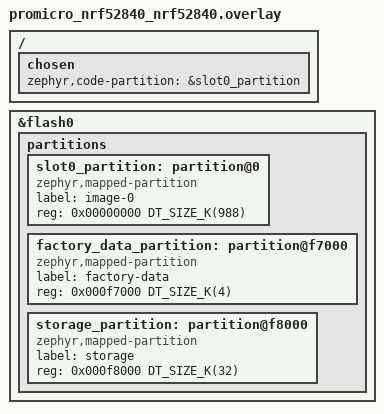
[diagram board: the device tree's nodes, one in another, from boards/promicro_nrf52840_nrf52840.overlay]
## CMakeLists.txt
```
# BLE-to-Matter-over-Thread gateway.
# Based on the nRF Connect SDK Matter Bridge application
# (Copyright (c) 2023 Nordic Semiconductor ASA, LicenseRef-Nordic-5-Clause).
#

cmake_minimum_required(VERSION 3.20.0)

find_package(Zephyr HINTS $ENV{ZEPHYR_BASE})

project(ble-matter-gateway)

# Bridge core, Matter identity, network log: firmware/common
include(${CMAKE_CURRENT_SOURCE_DIR}/../common/common.cmake)

target_include_directories(app PRIVATE
  src
  src/ble
  src/ble/data_providers
  src/sensors
  src/thermostat
)

target_sources(app PRIVATE
  src/app_task.cpp
  src/main.cpp
  src/bridge_shell.cpp
  src/zcl_callbacks.cpp
  src/ble/ble_connectivity_manager.cpp
  src/ble/ble_bridged_device_factory.cpp
  ${GATEWAY_BRIDGED_DEVICE_TYPES}/temperature_sensor.cpp
  ${GATEWAY_BRIDGED_DEVICE_TYPES}/humidity_sensor.cpp
  ${GATEWAY_BRIDGED_DEVICE_TYPES}/thermostat.cpp
  src/thermostat/eq3_client.cpp
  src/ble/data_providers/ble_environmental_data_provider.cpp
  src/sensors/bthome.c
  src/sensors/sensor_scanner.c
  src/sensors/sensor_shell.cpp
  src/sensors/bthome_sensor_provider.cpp
  src/sensors/bthome_sensor_manager.cpp
)

# Status page (firmware/common/web): src/web/index.html and its JSON
target_sources_ifdef(CONFIG_GATEWAY_WEB app PRIVATE src/web_status.cpp)

ncs_configure_data_model()
```

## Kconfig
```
#
# BLE-to-Matter-over-Thread gateway.
# Based on the nRF Connect SDK Matter Bridge application
# (Copyright (c) 2023 Nordic Semiconductor, LicenseRef-Nordic-5-Clause).
#
mainmenu "BLE-to-Matter-over-Thread Gateway"

config BRIDGE_TEMPERATURE_SENSOR_BRIDGED_DEVICE
	bool "Support for Temperature Sensor bridged device"
	default y

config BRIDGE_HUMIDITY_SENSOR_BRIDGED_DEVICE
	bool "Support for Humidity Sensor bridged device"
	default y

# The gateway always bridges real Bluetooth LE devices; the simulated providers of
# the original sample were removed. The symbol is kept because the bridge core
# code uses it to enable the Bluetooth LE parts.
config BRIDGED_DEVICE_BT
	bool
	default y

config BT_CENTRAL
	default y

config BT_SCAN
	default y

config BT_SCAN_FILTER_ENABLE
	default y

# Configure how many Bluetooth LE service UUIDs the bridge can scan for.
config BT_SCAN_UUID_CNT
	default 2

config BT_SCAN_ADDRESS_CNT
	default 1

config BT_GATT_CLIENT
	default y

config BT_GATT_DM
	default y

config BT_EXT_ADV
	default y

config BT_SMP
	default y

if BT_SMP

config BT_SETTINGS
	default y

# Use two Bluetooth LE identities. The first one is used by the peripheral for Matter service
# advertising purposes, and the other is used by the bridge central.
config BT_ID_MAX
	default 2

config BT_EXT_ADV_LEGACY_SUPPORT
	default y

endif

config BRIDGE_BLE_DEVICE_POLLING_INTERVAL
	int "BLE humidity measurement readout polling interval in ms"
	default 3000

if BRIDGE_TEMPERATURE_SENSOR_BRIDGED_DEVICE

# Matter TemperatureMeasurement uses 0.01 degC. (The original sample used -20/60, i.e. -0.20..0.60 degC.)
config BRIDGE_TEMPERATURE_SENSOR_MIN_MEASURED_VALUE
	int "Minimum measured value of bridged temperature sensors (0.01 degC)"
	default -4000

config BRIDGE_TEMPERATURE_SENSOR_MAX_MEASURED_VALUE
	int "Maximum measured value of bridged temperature sensors (0.01 degC)"
	default 12500

endif

if BRIDGE_HUMIDITY_SENSOR_BRIDGED_DEVICE

# Matter RelativeHumidityMeasurement uses 0.01 %. (The original sample used 0/100, i.e. 0..1 %.)
config BRIDGE_HUMIDITY_SENSOR_MIN_MEASURED_VALUE
	int "Minimum measured value of bridged humidity sensors (0.01 %)"
	default 0

config BRIDGE_HUMIDITY_SENSOR_MAX_MEASURED_VALUE
	int "Maximum measured value of bridged humidity sensors (0.01 %)"
	default 10000

endif

menu "Gateway sensor scanner"

config GATEWAY_SENSOR_SCAN_INTERVAL
	int "Background scan interval (x0.625 ms)"
	default 160
	help
	  Time between scan windows of the background passive scan for BTHome sensors.
	  Default: 160 (100 ms).

config GATEWAY_SENSOR_SCAN_WINDOW
	int "Background scan window (x0.625 ms)"
	default 40
	help
	  Listening time per scan interval. Keep it well below the interval so Thread
	  keeps enough radio time. Default: 40 (25 ms, 25 % duty cycle).

config GATEWAY_SENSOR_SCAN_RETRY_MS
	int "Background scan restart check interval (ms)"
	default 2000

config GATEWAY_SENSOR_SEEN_MAX
	int "Number of sensors kept in the 'heard' table"
	default 16

config GATEWAY_SENSOR_SCAN_PAUSE_CONNECT_MS
	int "Background scan pause while a GATT connection is being created (ms)"
	default 5000

config GATEWAY_BTHOME_AUTO_ADD
	bool "Add BTHome sensors to Matter automatically"
	default y
	help
	  Add a sensor as a Temperature Sensor and a Humidity Sensor endpoint on its
	  first BTHome packet with measurements. Removed sensors are ignored from then
	  on (shell: gateway remove / gateway unignore).

config GATEWAY_BTHOME_MAX_SENSORS
	int "Maximum number of bridged BTHome devices (sensors and thermostats)"
	default 10
	help
	  Each device uses one bridge provider; a sensor uses two dynamic
	  endpoints, a thermostat one. See BRIDGE_MAX_BRIDGED_DEVICES_NUMBER and
	  BRIDGE_MAX_DYNAMIC_ENDPOINTS_NUMBER.

config GATEWAY_EQ3_NAME_WAIT_S
	int "Wait this long for a new eQ-3 thermostat's name before adding it (s)"
	default 20
	range 0 120
	help
	  A renamed eQ-3 thermostat airs "eQ3-<name>" in its scan responses; it is
	  added with the node label "<name>", which controllers take as the initial
	  name. While waiting the background scan runs actively. If no name arrives
	  in time, or the unit has the default name, the label is "Thermostat 3F02".
	  0 adds thermostats at once with the default label.

config GATEWAY_EQ3_NAME_RETRY_MIN
	int "Look again for the names of thermostats on the generated label (min)"
	default 10
	range 0 1440
	help
	  A thermostat whose name wasn't heard when it was added keeps the label
	  "Thermostat 3F02". Every this many minutes the background scan runs
	  actively for GATEWAY_EQ3_NAME_WAIT_S; once the name is heard, the label
	  changes to it and is stored. A label set by the controller is kept.
	  0 turns the search off.

config GATEWAY_BTHOME_IGNORE_MAX
	int "Maximum number of ignored BTHome sensor addresses"
	default 8

config GATEWAY_BTHOME_UNREACHABLE_TIMEOUT_S
	int "Report a sensor unreachable after this many seconds without packets"
	default 600

config GATEWAY_BTHOME_BATTERY_WARNING_PCT
	int "Battery level reported as low (%)"
	default 20
	help
	  At or below this level, the Power Source cluster reports
	  BatChargeLevel Warning.

config GATEWAY_BTHOME_BATTERY_CRITICAL_PCT
	int "Battery level reported as critical (%)"
	default 10
	help
	  At or below this level, the Power Source cluster reports
	  BatChargeLevel Critical and BatReplacementNeeded.

config GATEWAY_BTHOME_QUEUE_SIZE
	int "Readings queued between the Bluetooth and Matter threads"
	default 8

module = GATEWAY_SENSOR_SCANNER
module-str = Gateway sensor scanner
source "subsys/logging/Kconfig.template.log_config"

config GATEWAY_EQ3_TARGET_SETS_MANUAL
	bool "Setting a target switches the eQ-3 thermostat to manual mode"
	default y
	help
	  Sends 40 <manual | target> instead of 41 <target>, so the target
	  stays until the next change instead of only until the next switch
	  point of the thermostat's weekly schedule.

config GATEWAY_EQ3_QUEUE_SIZE
	int "eQ-3 commands that can wait while one runs"
	default 8
	help
	  Commands run one at a time, about 10 s each. A scene that changes
	  every thermostat queues one command per thermostat.

config GATEWAY_EQ3_ATTEMPTS
	int "Attempts per eQ-3 thermostat command"
	default 3

config GATEWAY_EQ3_ATTEMPT_TIMEOUT_S
	int "Time limit for one eQ-3 command attempt, connection included (s)"
	default 20

config GATEWAY_EQ3_CONNECT_TIMEOUT_MS
	int "Time to find the thermostat's advertisement when connecting (ms)"
	default 10000
	help
	  The thermostat advertises about once a second, but with Thread
	  sharing the radio many advertisements are missed: in a first test,
	  two 5 s windows passed without one.

module = GATEWAY_EQ3
module-str = Gateway eQ-3 thermostat client
source "subsys/logging/Kconfig.template.log_config"

endmenu

rsource "../common/Kconfig"
```

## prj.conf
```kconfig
#
# Copyright (c) 2023 Nordic Semiconductor ASA
#
# SPDX-License-Identifier: LicenseRef-Nordic-5-Clause
#

# This sample uses Kconfig.defaults to set options common for all
# samples. This file should contain only options specific for this sample
# or overrides of default values.

# Enable CHIP
CONFIG_CHIP=y
CONFIG_CHIP_PROJECT_CONFIG="src/chip_project_config.h"
CONFIG_CHIP_DEVICE_PRODUCT_NAME="BLE Gateway"

# Configure ZAP file name
CONFIG_NCS_SAMPLE_MATTER_ZAP_FILE_PATH="${APPLICATION_CONFIG_DIR}/src/default_zap/bridge.zap"

# 32770 == 0x8002 (example bridge)
CONFIG_CHIP_DEVICE_PRODUCT_ID=32770
CONFIG_STD_CPP17=y

# Enable Matter pairing automatically on application start.
CONFIG_CHIP_ENABLE_PAIRING_AUTOSTART=y

# Enable Matter extended announcement and increase duration to 1 hour.
CONFIG_CHIP_BLE_EXT_ADVERTISING=y
CONFIG_CHIP_BLE_ADVERTISING_DURATION=60

# Add support for LEDs and buttons on Nordic development kits
CONFIG_DK_LIBRARY=y

# Bluetooth Low Energy configuration
CONFIG_BT_DEVICE_NAME="BLEGateway"

# Other settings
CONFIG_THREAD_NAME=y
CONFIG_MPU_STACK_GUARD=y
CONFIG_RESET_ON_FATAL_ERROR=n
CONFIG_CHIP_LIB_SHELL=y
CONFIG_NCS_SAMPLE_MATTER_TEST_SHELL=y

# Reduce assert verbosity to save flash space.
CONFIG_ASSERT_NO_FILE_INFO=y

# Disable NFC onboarding
CONFIG_CHIP_NFC_ONBOARDING_PAYLOAD=n

# Reduce application size
CONFIG_USE_SEGGER_RTT=n

# Enable Factory Data feature
CONFIG_CHIP_FACTORY_DATA=y
CONFIG_CHIP_FACTORY_DATA_BUILD=y

# Increase heap size to accommodate the memory required for additional bridged devices.
CONFIG_CHIP_MALLOC_SYS_HEAP_SIZE=16384

# Enable Shell
CONFIG_SHELL=y

# Peak use was 864 of the default 1152 B (doc/measurements.md)
CONFIG_SYSTEM_WORKQUEUE_STACK_SIZE=1536

# eQ-3 thermostat client: log each command and its result.
CONFIG_GATEWAY_EQ3_LOG_LEVEL_INF=y

# eQ-3 connections (doc/measurements.md, 2026-11-05): bt_tx_processor peaked at
# 612 of 768 B, and GATT discovery took 396 of the 516 B system heap (128 B chunks).
CONFIG_BT_TX_PROCESSOR_STACK_SIZE=1024
CONFIG_HEAP_MEM_POOL_SIZE=1024

# Status page over HTTP (firmware/common/web). It needs TCP, which only OpenThread built
# from source has (the prebuilt Nordic library is built without it).
CONFIG_OPENTHREAD_SOURCES=y
CONFIG_GATEWAY_WEB=y
```

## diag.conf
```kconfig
# Diagnostics build for measurements (plan step 5). Not for normal use.
#   west build -b nrf52840dk/nrf52840 --sysbuild -d firmware/ble-gateway/build-diag firmware/ble-gateway -- -DEXTRA_CONF_FILE=diag.conf

# Matter heap watermarks (`matter stat`), OpenThread shell (`ot ...`), net and kernel shells
CONFIG_CHIP_MEMORY_PROFILING=y

# Stack high-water marks (`kernel thread stacks`) and CPU use per thread (`kernel thread list`)
CONFIG_INIT_STACKS=y
CONFIG_THREAD_STACK_INFO=y
CONFIG_THREAD_MONITOR=y
CONFIG_THREAD_RUNTIME_STATS=y
CONFIG_SCHED_THREAD_USAGE_ALL=y

# System heap statistics (`kernel heap`)
CONFIG_SYS_HEAP_RUNTIME_STATS=y
```

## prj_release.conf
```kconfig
#
# Copyright (c) 2023 Nordic Semiconductor ASA
#
# SPDX-License-Identifier: LicenseRef-Nordic-5-Clause
#

# This sample uses Kconfig.defaults to set options common for all
# samples. This file should contain only options specific for this sample
# or overrides of default values.

# Enable CHIP
CONFIG_CHIP=y
CONFIG_CHIP_PROJECT_CONFIG="src/chip_project_config.h"
CONFIG_CHIP_DEVICE_PRODUCT_NAME="BLE Gateway"

# Configure ZAP file name
CONFIG_NCS_SAMPLE_MATTER_ZAP_FILE_PATH="${APPLICATION_CONFIG_DIR}/src/default_zap/bridge.zap"

# 32770 == 0x8002 (example bridge)
CONFIG_CHIP_DEVICE_PRODUCT_ID=32770
CONFIG_STD_CPP17=y

# Enable Matter pairing automatically on application start.
CONFIG_CHIP_ENABLE_PAIRING_AUTOSTART=y

# Enable Matter extended announcement and increase duration to 1 hour.
CONFIG_CHIP_BLE_EXT_ADVERTISING=y
CONFIG_CHIP_BLE_ADVERTISING_DURATION=60

# Add support for LEDs and buttons on Nordic development kits
CONFIG_DK_LIBRARY=y

# Bluetooth Low Energy configuration
CONFIG_BT_DEVICE_NAME="BLEGateway"

# Enable system reset on fatal error
CONFIG_RESET_ON_FATAL_ERROR=y

# Disable all debug features
CONFIG_USE_SEGGER_RTT=n
CONFIG_OPENTHREAD_SHELL=n
CONFIG_LOG=n
CONFIG_LOG_MODE_MINIMAL=n
CONFIG_ASSERT_VERBOSE=n
CONFIG_ASSERT_NO_FILE_INFO=y
CONFIG_PRINTK=n
CONFIG_PRINTK_SYNC=n
CONFIG_THREAD_NAME=n
CONFIG_BOOT_BANNER=n

# Disable NFC onboarding
CONFIG_CHIP_NFC_ONBOARDING_PAYLOAD=n

# Enable Factory Data feature
CONFIG_CHIP_FACTORY_DATA=y
CONFIG_CHIP_FACTORY_DATA_BUILD=y

# Enable the Read Client for binding purposes
CONFIG_CHIP_ENABLE_READ_CLIENT=y

# Enable Watchdog
CONFIG_NCS_SAMPLE_MATTER_WATCHDOG=y

# Enable LTO to decrease the flash usage.
CONFIG_LTO=y
CONFIG_ISR_TABLES_LOCAL_DECLARATION=y

# Increase heap size to accommodate the memory required for additional bridged devices.
CONFIG_CHIP_MALLOC_SYS_HEAP_SIZE=16384

# Enable Shell
CONFIG_SHELL=y

# Peak use was 864 of the default 1152 B (doc/measurements.md)
CONFIG_SYSTEM_WORKQUEUE_STACK_SIZE=1536

# eQ-3 connections (doc/measurements.md, 2026-11-05): bt_tx_processor peaked at
# 612 of 768 B, and GATT discovery took 396 of the 516 B system heap (128 B chunks).
CONFIG_BT_TX_PROCESSOR_STACK_SIZE=1024
CONFIG_HEAP_MEM_POOL_SIZE=1024

# Status page over HTTP (firmware/common/web). It needs TCP, which only OpenThread built
# from source has (the prebuilt Nordic library is built without it).
CONFIG_OPENTHREAD_SOURCES=y
CONFIG_GATEWAY_WEB=y
```

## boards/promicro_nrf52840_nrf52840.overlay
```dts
/*
 * Pro Micro nRF52840 (nice!nano clone, also sold as "SuperMini").
 *
 * No external flash and no MCUboot: the app starts at 0x0 and uses the
 * internal flash up to the factory data and settings partitions, which sit
 * at the same addresses as on the DK. The factory UF2 bootloader and the
 * SoftDevice area are erased by the first SWD flash.
 *
 * The variant that keeps the UF2 bootloader is promicro_nrf52840_nrf52840_uf2.overlay.
 */

/delete-node/ &boot_partition;
/delete-node/ &slot0_partition;
/delete-node/ &slot1_partition;
/delete-node/ &storage_partition;

/ {
	chosen {
		zephyr,code-partition = &slot0_partition;
	};
};

&flash0 {
	partitions {
		ranges;
		#address-cells = <1>;
		#size-cells = <1>;

		slot0_partition: partition@0 {
			compatible = "zephyr,mapped-partition";
			label = "image-0";
			reg = <0x00000000 DT_SIZE_K(988)>;
		};

		factory_data_partition: partition@f7000 {
			compatible = "zephyr,mapped-partition";
			label = "factory-data";
			reg = <0x000f7000 DT_SIZE_K(4)>;
		};

		storage_partition: partition@f8000 {
			compatible = "zephyr,mapped-partition";
			label = "storage";
			reg = <0x000f8000 DT_SIZE_K(32)>;
		};
	};
};

#include "promicro_nrf52840_common.dtsi"
```

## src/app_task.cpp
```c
/*
 * Copyright (c) 2023 Nordic Semiconductor ASA
 *
 * SPDX-License-Identifier: LicenseRef-Nordic-5-Clause
 */

#include "app_task.h"
#include "sensor_scanner.h"
#include "bthome_sensor_manager.h"
#ifdef CONFIG_GATEWAY_IDENTITY_FROM_CHIP_ID
#include "identity/chip_id_identity.h"
#endif
#ifdef CONFIG_GATEWAY_NET_LOG
#include "netlog/net_log.h"
#endif
#ifdef CONFIG_GATEWAY_WEB
#include "web/web_server.h"
#include "web_status.h"
#endif

#ifdef CONFIG_BRIDGED_DEVICE_BT
#include "ble_bridged_device_factory.h"
#else
#include "simulated_bridged_device_factory.h"
#endif /* CONFIG_BRIDGED_DEVICE_BT */

#include "app/matter_init.h"
#include "app/task_executor.h"
#include "board/board.h"
#include "bridge_manager.h"
#include "bridge_storage_manager.h"
#include "clusters/identify.h"

#ifdef CONFIG_BRIDGED_DEVICE_BT
#include "ble_connectivity_manager.h"
#endif

#include <app-common/zap-generated/attributes/Accessors.h>
#include <app-common/zap-generated/ids/Attributes.h>
#include <app-common/zap-generated/ids/Clusters.h>
#include <setup_payload/OnboardingCodesUtil.h>

#ifdef CONFIG_BRIDGED_DEVICE_BT
#include <bluetooth/services/lbs.h>
#endif /* CONFIG_BRIDGED_DEVICE_BT */
#include <zephyr/logging/log.h>

#ifdef CONFIG_BRIDGE_SMART_PLUG_SUPPORT
#define APPLICATION_BUTTON_MASK DK_BTN2_MSK
#endif /* CONFIG_BRIDGE_SMART_PLUG_SUPPORT */

LOG_MODULE_DECLARE(app, CONFIG_CHIP_APP_LOG_LEVEL);

using namespace ::chip;
using namespace ::chip::app;
using namespace ::chip::DeviceLayer;

namespace
{

constexpr EndpointId kBridgeEndpointId = 1;

#ifndef CONFIG_BRIDGE_SMART_PLUG_SUPPORT
/* Trigger effect is enabled for the bridge device */
Nrf::Matter::IdentifyCluster sIdentifyCluster(kBridgeEndpointId, true);
#else
Nrf::Matter::IdentifyCluster sIdentifyCluster(kBridgeEndpointId);
#endif

#ifdef CONFIG_BRIDGED_DEVICE_BT
const bt_uuid *sUuidLbs = BT_UUID_LBS;
const bt_uuid *sUuidEs = BT_UUID_ESS;
const bt_uuid *sUuidServices[] = { sUuidLbs, sUuidEs };
constexpr uint8_t kUuidServicesNumber = ARRAY_SIZE(sUuidServices);
/**
 * @brief Blink rates for indication the BLE Connectivity Manager state.
 *
 */
constexpr uint32_t kPairingBlinkRate{ 100 };
constexpr uint32_t kScanningBlinkRate_ms{ 300 };
constexpr uint32_t kLostBlinkRate_ms{ 1000 };
#ifndef CONFIG_BRIDGE_SMART_PLUG_SUPPORT
void BLEStateChangeCallback(Nrf::BLEConnectivityManager::State state)
{
	switch (state) {
	case Nrf::BLEConnectivityManager::State::Connected:
		Nrf::PostTask([] { Nrf::GetBoard().GetLED(Nrf::DeviceLeds::LED2).Set(true); });
		break;
	case Nrf::BLEConnectivityManager::State::Scanning:
		Nrf::PostTask([] {
			Nrf::GetBoard()
				.GetLED(Nrf::DeviceLeds::LED2)
				.Blink(kScanningBlinkRate_ms, kScanningBlinkRate_ms);
		});
		break;
	case Nrf::BLEConnectivityManager::State::LostDevice:
		Nrf::PostTask([] {
			Nrf::GetBoard().GetLED(Nrf::DeviceLeds::LED2).Blink(kLostBlinkRate_ms, kLostBlinkRate_ms);
		});
		break;
	case Nrf::BLEConnectivityManager::State::Pairing:
		Nrf::PostTask([] {
			Nrf::GetBoard().GetLED(Nrf::DeviceLeds::LED2).Blink(kPairingBlinkRate, kPairingBlinkRate);
		});
		break;
	default:
		Nrf::PostTask([] { Nrf::GetBoard().GetLED(Nrf::DeviceLeds::LED2).Set(false); });
	}
}
#endif /* CONFIG_BRIDGE_SMART_PLUG_SUPPORT */

#endif /* CONFIG_BRIDGED_DEVICE_BT */

#ifndef CONFIG_CHIP_FACTORY_RESET_ERASE_SETTINGS
void AppFactoryResetHandler(const ChipDeviceEvent *event, intptr_t /* unused */)
{
	switch (event->Type) {
	case DeviceEventType::kFactoryReset:
		Nrf::BridgeStorageManager::Instance().FactoryReset();
		break;
	default:
		break;
	}
}
#endif

#ifdef CONFIG_GATEWAY_IDENTITY_FROM_CHIP_ID
Gateway::ChipIdFactoryDataProvider sChipIdFactoryDataProvider;
#endif
} /* namespace */

CHIP_ERROR AppTask::RestoreBridgedDevices()
{
	uint8_t count;
	uint8_t indexes[Nrf::BridgeManager::kMaxBridgedDevices] = { 0 };
	size_t indexesCount = 0;

	if (!Nrf::BridgeStorageManager::Instance().LoadBridgedDevicesCount(count)) {
		LOG_INF("No bridged devices to load from the storage.");
		return CHIP_NO_ERROR;
	}

	if (!Nrf::BridgeStorageManager::Instance().LoadBridgedDevicesIndexes(
		    indexes, Nrf::BridgeManager::kMaxBridgedDevices, indexesCount)) {
		return CHIP_NO_ERROR;
	}

	/* Load all devices based on the read count number. */
	for (size_t i = 0; i < indexesCount; i++) {
		Nrf::BridgeStorageManager::BridgedDevice device;
#ifdef CONFIG_BRIDGED_DEVICE_BT
		/* GATT devices store only their address; BTHome sensors add a kind marker. */
		Gateway::StoredDeviceUserData userData{};
		device.mUserData = reinterpret_cast<uint8_t *>(&userData);
		device.mUserDataSize = sizeof(userData);
#endif

		if (!Nrf::BridgeStorageManager::Instance().LoadBridgedDevice(device, indexes[i])) {
			return CHIP_ERROR_NOT_FOUND;
		}

		LOG_INF("Loaded bridged device on endpoint id %d from the storage", device.mEndpointId);

#ifdef CONFIG_BRIDGED_DEVICE_BT
		if (device.mUserDataSize == sizeof(userData) &&
		    userData.mKind == Gateway::StoredDeviceUserData::kBTHomeSensor) {
			Gateway::BTHomeSensorManager::Instance().Restore(userData.mAddr, device.mDeviceType,
									 device.mUniqueID, device.mNodeLabel,
									 indexes[i], device.mEndpointId);
		} else {
			BleBridgedDeviceFactory::CreateDevice(device.mDeviceType, userData.mAddr, device.mUniqueID,
							      device.mNodeLabel, indexes[i], device.mEndpointId);
		}
#else
		SimulatedBridgedDeviceFactory::CreateDevice(device.mDeviceType, device.mUniqueID, device.mNodeLabel,
							    chip::Optional<uint8_t>(indexes[i]),
							    chip::Optional<uint16_t>(device.mEndpointId));
#endif
	}
	return CHIP_NO_ERROR;
}
#ifdef CONFIG_BRIDGE_SMART_PLUG_SUPPORT
void AppTask::SmartplugOnOffEventHandler()
{
	SystemLayer().ScheduleLambda([] {
		bool newState = !Nrf::GetBoard().GetLED(Nrf::DeviceLeds::LED2).GetState();
		Protocols::InteractionModel::Status status =
			Clusters::OnOff::Attributes::OnOff::Set(kSmartplugEndpointId, newState);
		if (status != Protocols::InteractionModel::Status::Success) {
			LOG_ERR("Updating on/off cluster failed: %x", to_underlying(status));
		}
	});
}

void AppTask::ButtonEventHandler(Nrf::ButtonState state, Nrf::ButtonMask hasChanged)
{
	if ((APPLICATION_BUTTON_MASK & hasChanged) & state) {
		Nrf::PostTask([] { SmartplugOnOffEventHandler(); });
	}
}
#endif /* CONFIG_BRIDGE_SMART_PLUG_SUPPORT */

CHIP_ERROR AppTask::Init()
{
	/* Initialize Matter stack */
	ReturnErrorOnFailure(Nrf::Matter::PrepareServer(Nrf::Matter::InitData{
#ifdef CONFIG_GATEWAY_IDENTITY_FROM_CHIP_ID
		.mFactoryDataProvider = &sChipIdFactoryDataProvider,
#endif
		.mPostServerInitClbk = [] {
#ifdef CONFIG_BRIDGED_DEVICE_BT
#ifndef CONFIG_BRIDGE_SMART_PLUG_SUPPORT
		Nrf::BLEConnectivityManager::Instance().RegisterStateCallback(BLEStateChangeCallback);
#endif /* CONFIG_BRIDGE_SMART_PLUG_SUPPORT */
		/* Initialize BLE Connectivity Manager before the Bridge Manager, as it must be ready to recover
		 * devices loaded from persistent storage during the bridge init. */
		CHIP_ERROR bleInitError =
			Nrf::BLEConnectivityManager::Instance().Init(sUuidServices, kUuidServicesNumber);
		if (bleInitError != CHIP_NO_ERROR) {
			LOG_ERR("BLEConnectivityManager initialization failed");
			return bleInitError;
		}
#endif

		/* Background passive scan for advertisement-only sensors (BTHome). */
		if (sensor_scanner_init() != 0) {
			LOG_ERR("Sensor scanner initialization failed");
			return CHIP_ERROR_INTERNAL;
		}

		/* Load the BTHome ignore list before stored sensors are restored. */
		Gateway::BTHomeSensorManager::Instance().Init();

		/* Initialize bridge manager */
		CHIP_ERROR bridgeMgrInitError = Nrf::BridgeManager::Instance().Init(RestoreBridgedDevices);
		if (bridgeMgrInitError != CHIP_NO_ERROR) {
			LOG_ERR("BridgeManager initialization failed");
			return bridgeMgrInitError;
		}

		/* Bridge BTHome sensors heard by the scanner. */
		Gateway::BTHomeSensorManager::Instance().Start();
#ifdef CONFIG_GATEWAY_NET_LOG
		Gateway::NetLog::Init();
#endif
#ifdef CONFIG_GATEWAY_WEB
		Gateway::Web::Init(Gateway::WriteWebStatus);
#endif
		return CHIP_NO_ERROR;
	} }));
#ifdef CONFIG_BRIDGE_SMART_PLUG_SUPPORT
	/* onoff plug part add buttonEventHandler*/
	if (!Nrf::GetBoard().Init(ButtonEventHandler)) {
		LOG_ERR("User interface initialization failed.");
		return CHIP_ERROR_INCORRECT_STATE;
	}
#else
	if (!Nrf::GetBoard().Init()) {
		LOG_ERR("User interface initialization failed.");
		return CHIP_ERROR_INCORRECT_STATE;
	}
#endif
	/* Register Matter event handler that controls the connectivity status LED based on the captured Matter
	 * network state. */
	ReturnErrorOnFailure(Nrf::Matter::RegisterEventHandler(Nrf::Board::DefaultMatterEventHandler, 0));

#ifndef CONFIG_CHIP_FACTORY_RESET_ERASE_SETTINGS
	/* Register factory reset event handler.
	 * With this configuration we have to manually clean up the storage,
	 * as whole settings partition won't be erased.
	 * */
	ReturnErrorOnFailure(Nrf::Matter::RegisterEventHandler(AppFactoryResetHandler, 0));
#endif

	ReturnErrorOnFailure(sIdentifyCluster.Init());

	return Nrf::Matter::StartServer();
}

CHIP_ERROR AppTask::StartApp()
{
	ReturnErrorOnFailure(Init());

	while (true) {
		Nrf::DispatchNextTask();
	}

	return CHIP_NO_ERROR;
}
```

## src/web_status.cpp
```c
/*
 * Status JSON of the BLE gateway for the web page (src/web/index.html). See web_status.h.
 */

#include "web_status.h"

#include "bridge_manager.h"
#include "bthome_sensor_manager.h"
#include "sensor_scanner.h"
#include "web/status_json.h"

#include <zephyr/bluetooth/addr.h>
#include <zephyr/kernel.h>

#include <stdio.h>
#include <string.h>

using Gateway::BTHomeSensorManager;
using Gateway::Web::Json;

namespace
{

/* "A4:C1:38:0C:54:AA" and "public"/"random" from Zephyr's "A4:C1:38:0C:54:AA (public)". */
void WriteAddress(Json &j, const bt_addr_le_t &addr)
{
	char text[BT_ADDR_LE_STR_LEN];

	bt_addr_le_to_str(&addr, text, sizeof(text));
	j.Str("address", text, 17);
	j.Str("addressType", addr.type == BT_ADDR_LE_PUBLIC ? "public" : "random");
}

void WriteSensors(Json &j)
{
	static BTHomeSensorManager::SensorInfo sensors[BTHomeSensorManager::kMaxSensors];
	const size_t n = BTHomeSensorManager::Instance().GetSensors(sensors, ARRAY_SIZE(sensors));
	const int64_t now = k_uptime_get();

	j.Open("sensors", '[');
	for (size_t i = 0; i < n; i++) {
		const auto &s = sensors[i];
		const uint16_t endpoint = s.mThermostatEndpoint ? s.mThermostatEndpoint : s.mTemperatureEndpoint;
		const char *label = Nrf::BridgeManager::Instance().GetNodeLabel(endpoint);

		j.Open(nullptr, '{');
		WriteAddress(j, s.mAddr);
		j.Str("name", label ? label : "");
		j.Bool("thermostat", s.mThermostatEndpoint != 0);
		j.Int("endpoint", endpoint);
		if (!s.mThermostatEndpoint) {
			j.Int("humidityEndpoint", s.mHumidityEndpoint);
		}
		j.Bool("reachable", s.mReachable);
		if (s.mLastSeenMs > 0) {
			j.Int("lastSeenS", (now - s.mLastSeenMs) / 1000);
		} else {
			j.Null("lastSeenS");
		}
		if (s.mHasTemperature) {
			j.Int("temperature", s.mTemperature);
		} else {
			j.Null("temperature");
		}
		if (s.mHasHumidity) {
			j.Int("humidity", s.mHumidity);
		} else {
			j.Null("humidity");
		}
		j.Int("battery", s.mBattery);
		j.Close('}');
	}
	j.Close(']');
}

/* A reading's value, or null if the sensor hasn't sent it. */
void Field(Json &j, const bthome_reading &r, uint32_t field, const char *key, long long value)
{
	if (r.fields & field) {
		j.Int(key, value);
	} else {
		j.Null(key);
	}
}

void FlagField(Json &j, const bthome_reading &r, uint32_t field, const char *key, bool value)
{
	if (r.fields & field) {
		j.Bool(key, value);
	} else {
		j.Null(key);
	}
}

void WriteSeen(Json &j)
{
	static sensor_seen seen[CONFIG_GATEWAY_SENSOR_SEEN_MAX];
	const size_t n = sensor_scanner_get_seen(seen, ARRAY_SIZE(seen));
	const int64_t now = k_uptime_get();

	j.Open("scan", '{');
	j.Bool("running", sensor_scanner_is_scanning());
	j.Bool("active", sensor_scanner_is_active());
	j.Close('}');

	j.Open("seen", '[');
	for (size_t i = 0; i < n; i++) {
		const sensor_seen &s = seen[i];
		const bthome_reading &r = s.last;

		j.Open(nullptr, '{');
		WriteAddress(j, s.addr);
		j.Str("name", s.name);
		j.Int("rssi", s.rssi);
		j.Int("agoS", (now - s.last_seen_ms) / 1000);
		j.Int("packets", s.packets);
		j.Int("measurements", s.measurements);
		j.Int("maxGapS", s.max_gap_ms / 1000);
		Field(j, r, BTHOME_HAS_TEMPERATURE, "temperature", r.temperature_centi_c);
		Field(j, r, BTHOME_HAS_HUMIDITY, "humidity", r.humidity_centi_pct);
		Field(j, r, BTHOME_HAS_BATTERY, "battery", r.battery_pct);
		Field(j, r, BTHOME_HAS_VOLTAGE, "voltage", r.voltage_mv);
		if (r.fields & BTHOME_THERMOSTAT_FIELDS) {
			/* eQ-3 with eq3-custom-fw: the temperature above is the room temperature. */
			j.Open("thermostat", '{');
			Field(j, r, BTHOME_HAS_TEMPERATURE2, "target", r.temperature2_centi_c);
			Field(j, r, BTHOME_HAS_VALVE, "valve", r.valve_pct);
			Field(j, r, BTHOME_HAS_MODE, "mode", r.mode);
			FlagField(j, r, BTHOME_HAS_BOOST, "boost", r.boost);
			FlagField(j, r, BTHOME_HAS_WINDOW_OPEN, "windowOpen", r.window_open);
			FlagField(j, r, BTHOME_HAS_UNLOCKED, "locked", !r.unlocked);
			FlagField(j, r, BTHOME_HAS_BATTERY_LOW, "batteryLow", r.battery_low);
			FlagField(j, r, BTHOME_HAS_CONNECTED, "connected", r.connected);
			j.Close('}');
		}
		j.Close('}');
	}
	j.Close(']');
}

} /* namespace */

namespace Gateway
{

size_t WriteWebStatus(char *buf, size_t size)
{
	Json j(buf, size);

	j.Open(nullptr, '{');
	Gateway::Web::WriteCommonStatus(j);
	WriteSensors(j);
	WriteSeen(j);
	j.Close('}');
	return j.Done();
}

} /* namespace Gateway */
```

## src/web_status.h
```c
/*
 * Status JSON of the BLE gateway for the web page (src/web/index.html):
 * system, Thread, Matter, bridged BTHome sensors and eQ-3 thermostats, devices heard.
 */

#pragma once

#include <stddef.h>

namespace Gateway
{

/* A Gateway::Web::StatusWriter: Matter thread, returns 0 if the JSON does not fit. */
size_t WriteWebStatus(char *buf, size_t size);

} /* namespace Gateway */
```
